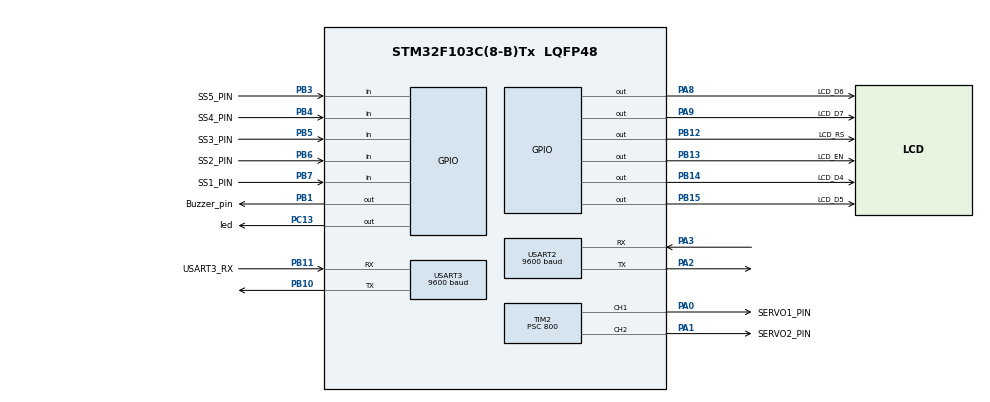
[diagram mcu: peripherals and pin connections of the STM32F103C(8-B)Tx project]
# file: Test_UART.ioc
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Mcu.Family=STM32F1
Mcu.Name=STM32F103C(8-B)Tx
Mcu.Package=LQFP48
NVIC.PriorityGroup=NVIC_PRIORITYGROUP_4
NVIC.USART2_IRQn=true\:0\:0\:true\:false\:true\:true\:true\:true
NVIC.USART3_IRQn=true\:0\:0\:true\:false\:true\:true\:true\:true
PA0-WKUP.GPIO_Label=SERVO1_PIN
PA0-WKUP.Signal=S_TIM2_CH1_ETR
PA1.GPIO_Label=SERVO2_PIN
PA1.Signal=S_TIM2_CH2
PA13.Mode=Serial_Wire
PA13.Signal=SYS_JTMS-SWDIO
PA14.Mode=Serial_Wire
PA14.Signal=SYS_JTCK-SWCLK
PA2.Mode=Asynchronous
PA2.Signal=USART2_TX
PA3.Mode=Asynchronous
PA3.Signal=USART2_RX
PA8.GPIO_Label=LCD_D6
PA8.Signal=GPIO_Output
PA9.GPIO_Label=LCD_D7
PA9.Signal=GPIO_Output
PB1.GPIO_Label=Buzzer_pin
PB1.Signal=GPIO_Output
PB10.Mode=Asynchronous
PB10.Signal=USART3_TX
PB11.GPIO_Label=USART3_RX
PB11.Mode=Asynchronous
PB11.Signal=USART3_RX
PB12.GPIO_Label=LCD_RS
PB12.Signal=GPIO_Output
PB13.GPIO_Label=LCD_EN
PB13.Signal=GPIO_Output
PB14.GPIO_Label=LCD_D4
PB14.Signal=GPIO_Output
PB15.GPIO_Label=LCD_D5
PB15.Signal=GPIO_Output
PB3.GPIO_Label=SS5_PIN
PB3.GPIO_PuPd=GPIO_PULLUP
PB3.Signal=GPIO_Input
PB4.GPIO_Label=SS4_PIN
PB4.GPIO_PuPd=GPIO_PULLUP
PB4.Signal=GPIO_Input
PB5.GPIO_Label=SS3_PIN
PB5.GPIO_PuPd=GPIO_PULLUP
PB5.Signal=GPIO_Input
PB6.GPIO_Label=SS2_PIN
PB6.GPIO_PuPd=GPIO_PULLUP
PB6.Signal=GPIO_Input
PB7.GPIO_Label=SS1_PIN
PB7.GPIO_Mode=GPIO_MODE_INPUT
PB7.GPIO_PuPd=GPIO_PULLUP
PB7.Signal=GPIO_Input
PC13-TAMPER-RTC.GPIO_Label=led
PC13-TAMPER-RTC.GPIO_PuPd=GPIO_NOPULL
PC13-TAMPER-RTC.GPIO_Speed=GPIO_SPEED_FREQ_MEDIUM
PC13-TAMPER-RTC.PinState=GPIO_PIN_RESET
PC13-TAMPER-RTC.Signal=GPIO_Output
ProjectManager.HeapSize=0x200
ProjectManager.StackSize=0x400
ProjectManager.TargetToolchain=STM32CubeIDE
RCC.APB1Freq_Value=8000000
RCC.APB2Freq_Value=8000000
SH.S_TIM2_CH1_ETR.0=TIM2_CH1,PWM Generation1 CH1
SH.S_TIM2_CH2.0=TIM2_CH2,PWM Generation2 CH2
TIM2.AutoReloadPreload=TIM_AUTORELOAD_PRELOAD_ENABLE
TIM2.Channel-PWM\ Generation1\ CH1=TIM_CHANNEL_1
TIM2.Channel-PWM\ Generation2\ CH2=TIM_CHANNEL_2
TIM2.Period=200
TIM2.Prescaler=800
TIM2.Pulse-PWM\ Generation1\ CH1=0
TIM2.Pulse-PWM\ Generation2\ CH2=0
TIM2.TIM_MasterSlaveMode=TIM_MASTERSLAVEMODE_DISABLE
USART2.BaudRate=9600
USART2.VirtualMode=VM_ASYNC
USART3.BaudRate=9600
USART3.VirtualMode=VM_ASYNC
VP_TIM2_VS_ClockSourceINT.Mode=Internal
VP_TIM2_VS_ClockSourceITR.Mode=TriggerSource_ITR0
board=custom

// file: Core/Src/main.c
/* USER CODE BEGIN Header */
/**
  ******************************************************************************
  * @file           : main.c
  * @brief          : Main program body
  ******************************************************************************
  * @attention
  *
  * Copyright (c) 2023 STMicroelectronics.
  * All rights reserved.
  *
  * This software is licensed under terms that can be found in the LICENSE file
  * in the root directory of this software component.
  * If no LICENSE file comes with this software, it is provided AS-IS.
  *
  ******************************************************************************
  */
/* USER CODE END Header */
#include "main.h"

/* USER CODE BEGIN Includes */
#include <Park.h>
#include <lcd.h>
#include <Sensor.h>
/* USER CODE END Includes */

TIM_HandleTypeDef htim2;

UART_HandleTypeDef huart2;
UART_HandleTypeDef huart3;

void SystemClock_Config(void);
static void MX_GPIO_Init(void);
static void MX_TIM2_Init(void);
static void MX_USART2_UART_Init(void);
static void MX_USART3_UART_Init(void);

int main(void)
{

  /* MCU Configuration--------------------------------------------------------*/

  /* Reset of all peripherals, Initializes the Flash interface and the Systick. */
  HAL_Init();

  /* Configure the system clock */
  SystemClock_Config();

  /* Initialize all configured peripherals */
  MX_GPIO_Init();
  MX_TIM2_Init();
  MX_USART2_UART_Init();
  MX_USART3_UART_Init();
  /* USER CODE BEGIN 2 */
  HAL_UART_Receive_IT(&huart3, &RFID_DATA, 1);
  HAL_UART_Receive_IT(&huart2, &COM_DATA, 1);
  HAL_TIM_PWM_Start(&htim2, TIM_CHANNEL_1);
  HAL_TIM_PWM_Start(&htim2, TIM_CHANNEL_2);

  LCD_Init();
  LCD_Clear();
  /* USER CODE END 2 */

  /* Infinite loop */
  /* USER CODE BEGIN WHILE */
  while (1)
  {
	  SensorRead();
	  hien_thi();
  }

    /* USER CODE END WHILE */

}

void SystemClock_Config(void)
{
  RCC_OscInitTypeDef RCC_OscInitStruct = {0};
  RCC_ClkInitTypeDef RCC_ClkInitStruct = {0};

  /** Initializes the RCC Oscillators according to the specified parameters
  * in the RCC_OscInitTypeDef structure.
  */
  RCC_OscInitStruct.OscillatorType = RCC_OSCILLATORTYPE_HSI;
  RCC_OscInitStruct.HSIState = RCC_HSI_ON;
  RCC_OscInitStruct.HSICalibrationValue = RCC_HSICALIBRATION_DEFAULT;
  RCC_OscInitStruct.PLL.PLLState = RCC_PLL_NONE;
  if (HAL_RCC_OscConfig(&RCC_OscInitStruct) != HAL_OK)
  {
    Error_Handler();
  }

  /** Initializes the CPU, AHB and APB buses clocks
  */
  RCC_ClkInitStruct.ClockType = RCC_CLOCKTYPE_HCLK|RCC_CLOCKTYPE_SYSCLK
                              |RCC_CLOCKTYPE_PCLK1|RCC_CLOCKTYPE_PCLK2;
  RCC_ClkInitStruct.SYSCLKSource = RCC_SYSCLKSOURCE_HSI;
  RCC_ClkInitStruct.AHBCLKDivider = RCC_SYSCLK_DIV1;
  RCC_ClkInitStruct.APB1CLKDivider = RCC_HCLK_DIV1;
  RCC_ClkInitStruct.APB2CLKDivider = RCC_HCLK_DIV1;

  if (HAL_RCC_ClockConfig(&RCC_ClkInitStruct, FLASH_LATENCY_0) != HAL_OK)
  {
    Error_Handler();
  }
}

static void MX_TIM2_Init(void)
{

  TIM_ClockConfigTypeDef sClockSourceConfig = {0};
  TIM_SlaveConfigTypeDef sSlaveConfig = {0};
  TIM_MasterConfigTypeDef sMasterConfig = {0};
  TIM_OC_InitTypeDef sConfigOC = {0};

  htim2.Instance = TIM2;
  htim2.Init.Prescaler = 800;
  htim2.Init.CounterMode = TIM_COUNTERMODE_UP;
  htim2.Init.Period = 200;
  htim2.Init.ClockDivision = TIM_CLOCKDIVISION_DIV1;
  htim2.Init.AutoReloadPreload = TIM_AUTORELOAD_PRELOAD_ENABLE;
  if (HAL_TIM_Base_Init(&htim2) != HAL_OK)
  {
    Error_Handler();
  }
  sClockSourceConfig.ClockSource = TIM_CLOCKSOURCE_INTERNAL;
  if (HAL_TIM_ConfigClockSource(&htim2, &sClockSourceConfig) != HAL_OK)
  {
    Error_Handler();
  }
  if (HAL_TIM_PWM_Init(&htim2) != HAL_OK)
  {
    Error_Handler();
  }
  sSlaveConfig.SlaveMode = TIM_SLAVEMODE_DISABLE;
  sSlaveConfig.InputTrigger = TIM_TS_ITR0;
  if (HAL_TIM_SlaveConfigSynchro(&htim2, &sSlaveConfig) != HAL_OK)
  {
    Error_Handler();
  }
  sMasterConfig.MasterOutputTrigger = TIM_TRGO_RESET;
  sMasterConfig.MasterSlaveMode = TIM_MASTERSLAVEMODE_DISABLE;
  if (HAL_TIMEx_MasterConfigSynchronization(&htim2, &sMasterConfig) != HAL_OK)
  {
    Error_Handler();
  }
  sConfigOC.OCMode = TIM_OCMODE_PWM1;
  sConfigOC.Pulse = 0;
  sConfigOC.OCPolarity = TIM_OCPOLARITY_HIGH;
  sConfigOC.OCFastMode = TIM_OCFAST_DISABLE;
  if (HAL_TIM_PWM_ConfigChannel(&htim2, &sConfigOC, TIM_CHANNEL_1) != HAL_OK)
  {
    Error_Handler();
  }
  if (HAL_TIM_PWM_ConfigChannel(&htim2, &sConfigOC, TIM_CHANNEL_2) != HAL_OK)
  {
    Error_Handler();
  }
  HAL_TIM_MspPostInit(&htim2);

}

static void MX_USART2_UART_Init(void)
{

  huart2.Instance = USART2;
  huart2.Init.BaudRate = 9600;
  huart2.Init.WordLength = UART_WORDLENGTH_8B;
  huart2.Init.StopBits = UART_STOPBITS_1;
  huart2.Init.Parity = UART_PARITY_NONE;
  huart2.Init.Mode = UART_MODE_TX_RX;
  huart2.Init.HwFlowCtl = UART_HWCONTROL_NONE;
  huart2.Init.OverSampling = UART_OVERSAMPLING_16;
  if (HAL_UART_Init(&huart2) != HAL_OK)
  {
    Error_Handler();
  }

}

static void MX_USART3_UART_Init(void)
{

  huart3.Instance = USART3;
  huart3.Init.BaudRate = 9600;
  huart3.Init.WordLength = UART_WORDLENGTH_8B;
  huart3.Init.StopBits = UART_STOPBITS_1;
  huart3.Init.Parity = UART_PARITY_NONE;
  huart3.Init.Mode = UART_MODE_TX_RX;
  huart3.Init.HwFlowCtl = UART_HWCONTROL_NONE;
  huart3.Init.OverSampling = UART_OVERSAMPLING_16;
  if (HAL_UART_Init(&huart3) != HAL_OK)
  {
    Error_Handler();
  }

}

static void MX_GPIO_Init(void)
{
  GPIO_InitTypeDef GPIO_InitStruct = {0};

  /* GPIO Ports Clock Enable */
  __HAL_RCC_GPIOC_CLK_ENABLE();
  __HAL_RCC_GPIOA_CLK_ENABLE();
  __HAL_RCC_GPIOB_CLK_ENABLE();

  /*Configure GPIO pin Output Level */
  HAL_GPIO_WritePin(led_GPIO_Port, led_Pin, GPIO_PIN_RESET);

  /*Configure GPIO pin Output Level */
  HAL_GPIO_WritePin(GPIOB, Buzzer_pin_Pin|LCD_RS_Pin|LCD_EN_Pin|LCD_D4_Pin
                          |LCD_D5_Pin, GPIO_PIN_RESET);

  /*Configure GPIO pin Output Level */
  HAL_GPIO_WritePin(GPIOA, LCD_D6_Pin|LCD_D7_Pin, GPIO_PIN_RESET);

  /*Configure GPIO pin : led_Pin */
  GPIO_InitStruct.Pin = led_Pin;
  GPIO_InitStruct.Mode = GPIO_MODE_OUTPUT_PP;
  GPIO_InitStruct.Pull = GPIO_NOPULL;
  GPIO_InitStruct.Speed = GPIO_SPEED_FREQ_MEDIUM;
  HAL_GPIO_Init(led_GPIO_Port, &GPIO_InitStruct);

  /*Configure GPIO pins : Buzzer_pin_Pin LCD_RS_Pin LCD_EN_Pin LCD_D4_Pin
                           LCD_D5_Pin */
  GPIO_InitStruct.Pin = Buzzer_pin_Pin|LCD_RS_Pin|LCD_EN_Pin|LCD_D4_Pin
                          |LCD_D5_Pin;
  GPIO_InitStruct.Mode = GPIO_MODE_OUTPUT_PP;
  GPIO_InitStruct.Pull = GPIO_NOPULL;
  GPIO_InitStruct.Speed = GPIO_SPEED_FREQ_LOW;
  HAL_GPIO_Init(GPIOB, &GPIO_InitStruct);

  /*Configure GPIO pins : LCD_D6_Pin LCD_D7_Pin */
  GPIO_InitStruct.Pin = LCD_D6_Pin|LCD_D7_Pin;
  GPIO_InitStruct.Mode = GPIO_MODE_OUTPUT_PP;
  GPIO_InitStruct.Pull = GPIO_NOPULL;
  GPIO_InitStruct.Speed = GPIO_SPEED_FREQ_LOW;
  HAL_GPIO_Init(GPIOA, &GPIO_InitStruct);

  /*Configure GPIO pins : SS5_PIN_Pin SS4_PIN_Pin SS3_PIN_Pin SS2_PIN_Pin
                           SS1_PIN_Pin */
  GPIO_InitStruct.Pin = SS5_PIN_Pin|SS4_PIN_Pin|SS3_PIN_Pin|SS2_PIN_Pin
                          |SS1_PIN_Pin;
  GPIO_InitStruct.Mode = GPIO_MODE_INPUT;
  GPIO_InitStruct.Pull = GPIO_PULLUP;
  HAL_GPIO_Init(GPIOB, &GPIO_InitStruct);

}

void Error_Handler(void)
{
  __disable_irq();
  while (1)
  {
  }
}
